AUTOSAR XML (schema 4.0)
package /ADAS_Components
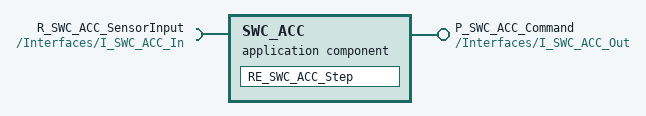
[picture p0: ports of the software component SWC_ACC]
  application sw component type SWC_ACC  # AUTOSAR Application SWC SWC_ACC for ADAS control
    provide port P_SWC_ACC_Command: provided-interface=/Interfaces/I_SWC_ACC_Out
    require port R_SWC_ACC_SensorInput: required-interface=/Interfaces/I_SWC_ACC_In
    behavior SWC_ACC_Behavior
      runnable RE_SWC_ACC_Step: symbol=SWC_ACC_Step
